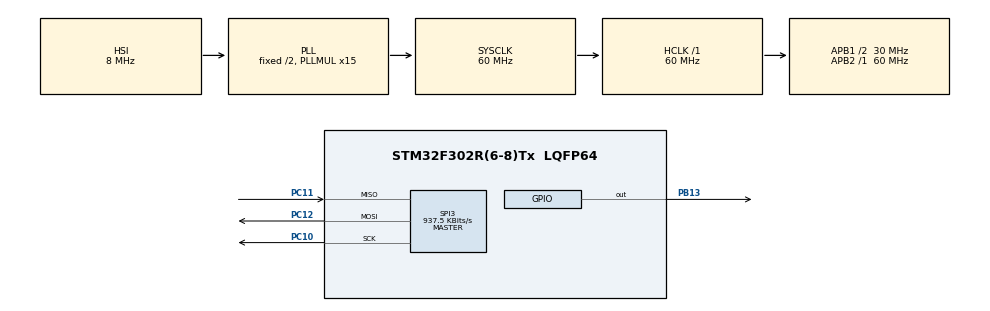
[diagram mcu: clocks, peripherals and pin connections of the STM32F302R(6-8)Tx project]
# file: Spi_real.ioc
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Mcu.Family=STM32F3
Mcu.Name=STM32F302R(6-8)Tx
Mcu.Package=LQFP64
NVIC.PriorityGroup=NVIC_PRIORITYGROUP_4
PA13.Mode=Serial_Wire
PA13.Signal=SYS_JTMS-SWDIO
PA14.Mode=Serial_Wire
PA14.Signal=SYS_JTCK-SWCLK
PB13.Signal=GPIO_Output
PC10.Mode=Full_Duplex_Master
PC10.Signal=SPI3_SCK
PC11.Mode=Full_Duplex_Master
PC11.Signal=SPI3_MISO
PC12.Mode=Full_Duplex_Master
PC12.Signal=SPI3_MOSI
ProjectManager.HeapSize=0x200
ProjectManager.StackSize=0x400
ProjectManager.TargetToolchain=STM32CubeIDE
RCC.AHBFreq_Value=60000000
RCC.APB1CLKDivider=RCC_HCLK_DIV2
RCC.APB1Freq_Value=30000000
RCC.APB1TimFreq_Value=60000000
RCC.APB2Freq_Value=60000000
RCC.APB2TimFreq_Value=60000000
RCC.CortexFreq_Value=60000000
RCC.HCLKFreq_Value=60000000
RCC.HSE_VALUE=8000000
RCC.HSI_VALUE=8000000
RCC.LSE_VALUE=32768
RCC.PLLMUL=RCC_PLL_MUL15
RCC.SYSCLKFreq_VALUE=60000000
RCC.SYSCLKSourceVirtual=RCC_SYSCLKSOURCE_PLLCLK
RCC.USBFreq_Value=60000000
SPI3.BaudRatePrescaler=SPI_BAUDRATEPRESCALER_32
SPI3.CalculateBaudRate=937.5 KBits/s
SPI3.DataSize=SPI_DATASIZE_8BIT
SPI3.Direction=SPI_DIRECTION_2LINES
SPI3.Mode=SPI_MODE_MASTER
SPI3.NSSPMode=SPI_NSS_PULSE_DISABLE
SPI3.VirtualType=VM_MASTER
board=custom

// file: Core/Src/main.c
/* USER CODE BEGIN Header */
/**
  ******************************************************************************
  * @file           : main.c
  * @brief          : Main program body
  ******************************************************************************
  * @attention
  *
  * Copyright (c) 2024 STMicroelectronics.
  * All rights reserved.
  *
  * This software is licensed under terms that can be found in the LICENSE file
  * in the root directory of this software component.
  * If no LICENSE file comes with this software, it is provided AS-IS.
  *
  ******************************************************************************
  */
/* USER CODE END Header */

#include "main.h"

SPI_HandleTypeDef hspi3; // SPI handle for SPI3

void SystemClock_Config(void);
static void MX_GPIO_Init(void);
static void MX_SPI3_Init(void);

/**
  * @brief  Entry point for the application.
  * @retval int
  */
int main(void)
{
  /* MCU Configuration--------------------------------------------------------*/

  /* Reset peripherals, initialize Flash interface and Systick */
  HAL_Init();

  /* Initialization */

  /* Configure system clock */
  SystemClock_Config();

  /* System Initialization */

  /* Initialize peripherals */
  MX_GPIO_Init();
  MX_SPI3_Init();
  /* USER CODE BEGIN 2 */
  DigiLed_init(&hspi3); // Initialize digital LEDs via SPI3

  /* USER CODE END 2 */

  /* Main processing loop */
  /* USER CODE BEGIN WHILE */
  while (1)
  {
    /* Loop body left empty for user code */
    /* USER CODE END WHILE */

  }
}

/**
  * @brief Configures the system clock.
  * @retval None
  */
void SystemClock_Config(void)
{
  RCC_OscInitTypeDef RCC_OscInitStruct = {0};
  RCC_ClkInitTypeDef RCC_ClkInitStruct = {0};

  /* Setup RCC Oscillators */
  RCC_OscInitStruct.OscillatorType = RCC_OSCILLATORTYPE_HSI;
  RCC_OscInitStruct.HSIState = RCC_HSI_ON;
  RCC_OscInitStruct.HSICalibrationValue = RCC_HSICALIBRATION_DEFAULT;
  RCC_OscInitStruct.PLL.PLLState = RCC_PLL_ON;
  RCC_OscInitStruct.PLL.PLLSource = RCC_PLLSOURCE_HSI;
  RCC_OscInitStruct.PLL.PLLMUL = RCC_PLL_MUL15;
  if (HAL_RCC_OscConfig(&RCC_OscInitStruct) != HAL_OK)
  {
    Error_Handler();
  }

  /* Initialize CPU, AHB, and APB clocks */
  RCC_ClkInitStruct.ClockType = RCC_CLOCKTYPE_HCLK|RCC_CLOCKTYPE_SYSCLK
                              |RCC_CLOCKTYPE_PCLK1|RCC_CLOCKTYPE_PCLK2;
  RCC_ClkInitStruct.SYSCLKSource = RCC_SYSCLKSOURCE_PLLCLK;
  RCC_ClkInitStruct.AHBCLKDivider = RCC_SYSCLK_DIV1;
  RCC_ClkInitStruct.APB1CLKDivider = RCC_HCLK_DIV2;
  RCC_ClkInitStruct.APB2CLKDivider = RCC_HCLK_DIV1;

  if (HAL_RCC_ClockConfig(&RCC_ClkInitStruct, FLASH_LATENCY_2) != HAL_OK)
  {
    Error_Handler();
  }
}

/**
  * @brief Initializes SPI3.
  * @retval None
  */
static void MX_SPI3_Init(void)
{
  /* Configure SPI3 parameters */
  hspi3.Instance = SPI3;
  hspi3.Init.Mode = SPI_MODE_MASTER;
  hspi3.Init.Direction = SPI_DIRECTION_2LINES;
  hspi3.Init.DataSize = SPI_DATASIZE_8BIT;
  hspi3.Init.CLKPolarity = SPI_POLARITY_LOW;
  hspi3.Init.CLKPhase = SPI_PHASE_1EDGE;
  hspi3.Init.NSS = SPI_NSS_SOFT;
  hspi3.Init.BaudRatePrescaler = SPI_BAUDRATEPRESCALER_32;
  hspi3.Init.FirstBit = SPI_FIRSTBIT_MSB;
  hspi3.Init.TIMode = SPI_TIMODE_DISABLE;
  hspi3.Init.CR
